# STM32L4x2 register map
File version: 2.3
CPU: CM4 r0p1, little endian, MPU, FPU, 4 interrupt priority bits
Registers are 32-bit, read-write, reset 0x0 unless marked. A register's access mark holds for its fields unless they carry their own. Offsets are from the block's base; [hi:lo] are bit positions; lines under a group give offsets from that group; {n}, {i} and the like mark numbered series; 'fields as' and 'values as' point back to an identical list.

## AES — Advanced encryption standard hardware accelerator
Base 0x50060000
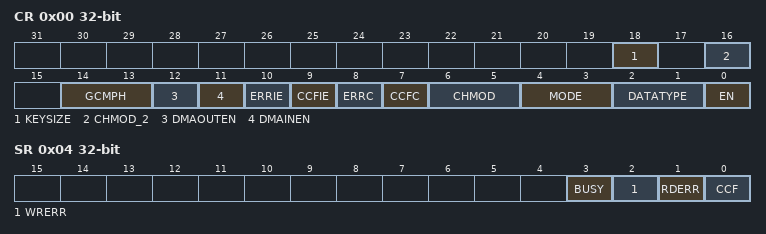
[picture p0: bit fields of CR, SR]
0x00 CR — control register
  [18] KEYSIZE — Key size selection
    0=AES128 (128); 1=AES256 (256)
  [16] CHMOD_2 — Chaining mode selection, bit [2]
    0=CHMOD (Mode as per CHMOD (ECB, CBC, CTR, GCM)); 1=CCM (Counter with CBC-MAC (CCM) - CHMOD must be 0 (ECB))
  [14:13] GCMPH — GCM or CCM phase selection
    0=Init phase; 1=Header phase; 2=Payload phase; 3=Final Phase
  [12] DMAOUTEN — Enable DMA management of data output phase
    0=Disable DMA Output; 1=Enabled DMA Output
  [11] DMAINEN — Enable DMA management of data input phase
    0=Disable DMA Input; 1=Enable DMA Input
  [10] ERRIE — Error interrupt enable
    0=Disabled (Disable (mask) error interrupt); 1=Enabled (Enable error interrupt)
  [9] CCFIE — CCF flag interrupt enable
    0=Disabled (Disable (mask) CCF interrupt); 1=Enabled (Enable CCF interrupt)
  [8] ERRC — Error clear
    on write: 1=Clear RDERR and WRERR flags
  [7] CCFC — Computation Complete Flag Clear
    on write: 1=Clear computation complete flag
  [6:5] CHMOD — AES chaining mode
    0=ECB (Electronic codebook (ECB) / Counter with CBC-MAC (CCM) if CHMOD2 is 1); 1=CBC (Cipher-block chaining (CBC)); 2=CTR (Counter mode (CTR)); 3=GCM (Galois counter mode (GCM) and Galois message authentication code (GMAC))
  [4:3] MODE — AES operating mode
    0=Mode 1: encryption; 1=Mode 2: key derivation (or key preparation for ECB/CBC decryption); 2=Mode 3: decryption; 3=Mode 4: key derivation then single decryption
  [2:1] DATATYPE — Data type selection (for data in and data out to/from the cryptographic block)
    0=None (Word); 1=Half-word (16-bit); 2=Byte (8-bit); 3=Bit
  [0] EN — AES enable
    0=Disabled (Disable AES); 1=Enabled (Enable AES)
0x04 SR ro — status register
  [3] BUSY
    0=Idle; 1=Busy
  [2] WRERR — Write error flag
    0=NoError (Write error not detected); 1=Error (Write error detected)
  [1] RDERR — Read error flag
    0=NoError (Read error not detected); 1=Error (Read error detected)
  [0] CCF — Computation complete flag
    0=Complete (Computation complete); 1=NotComplete (Computation not complete)
0x08 DINR — data input register
  [31:0] DIN — Data Input Register
0x0C DOUTR ro — data output register
  [31:0] DOUT — Data output register
0x10 KEYR0 — key register 0
  [31:0] KEY — Data Output Register (LSB key [31:0])
0x14 KEYR1 — key register 1
  [31:0] KEY — AES key register (key [63:32])
0x18 KEYR2 — key register 2
  [31:0] KEY — AES key register (key [95:64])
0x1C KEYR3 — key register 3
  [31:0] KEY — AES key register (MSB key [127:96])
0x20 IVR0 — initialization vector register 0
  [31:0] IVI — initialization vector register (LSB IVR [31:0])
0x24 IVR1 — initialization vector register 1
  [31:0] IVI — Initialization Vector Register (IVR [63:32])
0x28 IVR2 — initialization vector register 2
  [31:0] IVI — Initialization Vector Register (IVR [95:64])
0x2C IVR3 — initialization vector register 3
  [31:0] IVI — Initialization Vector Register (MSB IVR [127:96])
{0x20+4i} KEYR{i} (i=4..7) — key register {i}
  [31:0] KEY — Cryptographic key, bits [{32i+31}:{32i}]
{0x40+4i} SUSP{i}R (i=0..7) — suspend registers
  [31:0] SUSP — AES suspend

## DMA1 — Direct memory access controller
Base 0x40020000
Same registers: DMA2 0x40020400
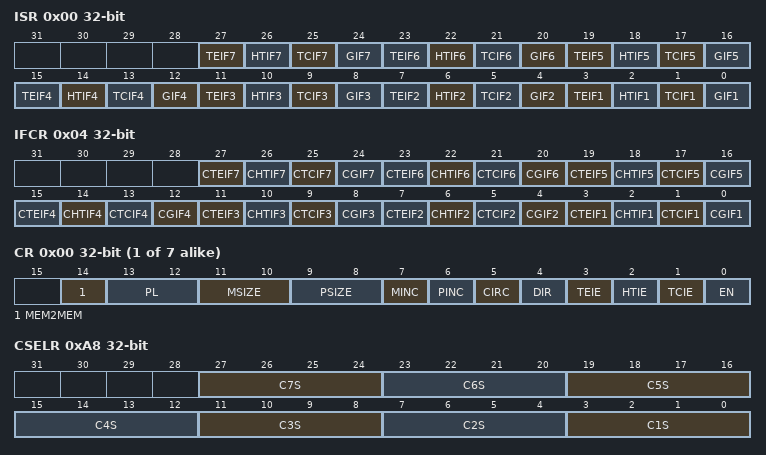
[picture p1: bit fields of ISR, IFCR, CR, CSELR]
0x00 ISR ro — interrupt status register
  [4n-1] TEIF{n} (n=1..7) — Channel {n} Transfer Error flag
    0=NoError (No transfer error); 1=Error (A transfer error has occured)
  [4n-2] HTIF{n} (n=1..7) — Channel {n} Half Transfer Complete flag
    0=NotHalf (No half transfer event); 1=Half (A half transfer event has occured)
  [4n-3] TCIF{n} (n=1..7) — Channel {n} Transfer Complete flag
    0=NotComplete (No transfer complete event); 1=Complete (A transfer complete event has occured)
  [4n-4] GIF{n} (n=1..7) — Channel {n} Global interrupt flag
    0=NoEvent (No transfer error, half event, complete event); 1=Event (A transfer error, half event or complete event has occured)
0x04 IFCR wo — interrupt flag clear register
  [4n-1] CTEIF{n} (n=1..7) — Channel {n} Transfer Error clear
    1=Clears the TEIF flag in the ISR register
  [4n-2] CHTIF{n} (n=1..7) — Channel {n} Half Transfer clear
    1=Clears the HTIF flag in the ISR register
  [4n-3] CTCIF{n} (n=1..7) — Channel {n} Transfer Complete clear
    1=Clears the TCIF flag in the ISR register
  [4n-4] CGIF{n} (n=1..7) — Channel {n} Global interrupt clear
    1=Clears the GIF, TEIF, HTIF, TCIF flags in the ISR register
0x08 CH{i} (i=1..7; step 0x14) group — Channel cluster: CCR?, CNDTR?, CPAR?, and CMAR? registers
  0x00 CR — channel x configuration register
    [14] MEM2MEM — Memory to memory mode
      0=Disabled (Memory to memory mode disabled); 1=Enabled (Memory to memory mode enabled)
    [13:12] PL — Channel priority level
      0=Low (Low priority); 1=Medium priority; 2=High priority; 3=Very high priority
    [11:10] MSIZE — Memory size
      0=Bits8 (8-bit size); 1=Bits16 (16-bit size); 2=Bits32 (32-bit size)
    [9:8] PSIZE — Peripheral size
      values as MSIZE
    [7] MINC — Memory increment mode
      0=Disabled (Increment mode disabled); 1=Enabled (Increment mode enabled)
    [6] PINC — Peripheral increment mode
      values as MINC
    [5] CIRC — Circular mode
      0=Disabled (Circular buffer disabled); 1=Enabled (Circular buffer enabled)
    [4] DIR — Data transfer direction
      0=FromPeripheral (Read from peripheral); 1=FromMemory (Read from memory)
    [3] TEIE — Transfer error interrupt enable
      0=Disabled (Transfer Error interrupt disabled); 1=Enabled (Transfer Error interrupt enabled)
    [2] HTIE — Half transfer interrupt enable
      0=Disabled (Half Transfer interrupt disabled); 1=Enabled (Half Transfer interrupt enabled)
    [1] TCIE — Transfer complete interrupt enable
      0=Disabled (Transfer Complete interrupt disabled); 1=Enabled (Transfer Complete interrupt enabled)
    [0] EN — Channel enable
      0=Disabled (Channel disabled); 1=Enabled (Channel enabled)
  0x04 NDTR — channel x number of data register
    [15:0] NDT — Number of data to transfer
  0x08 PAR — channel x peripheral address register
    [31:0] PA — Peripheral address
  0x0C MAR — channel x memory address register
    [31:0] MA — Memory address
0xA8 CSELR — channel selection register
  [all] fields
    0=NoMapping (Default mapping); {v}=Map{v} (Mapping {v}) (v=1..15)
  [4n-1:4n-4] C{n}S (n=1..7) — DMA channel {n} selection
